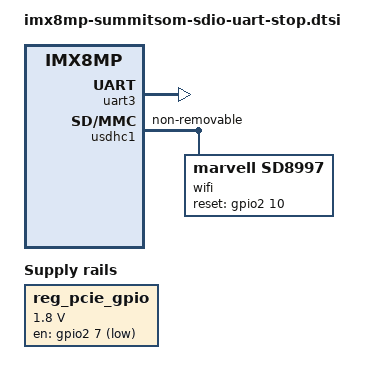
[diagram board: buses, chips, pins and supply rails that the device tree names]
// SPDX-License-Identifier: (GPL-2.0+ OR MIT)
/*
 * Copyright 2022 Laird Connectivity
 */

/ {
	reg_pcie_gpio: regulator-pcie-gpio {
		pinctrl-names = "default";
		pinctrl-0 = <&pinctrl_pcie_disable &pinctrl_pcie_reset>;

		compatible = "regulator-fixed";

		regulator-name = "PCIE GPIO";
		regulator-min-microvolt = <1800000>;
		regulator-max-microvolt = <1800000>;

		gpios = <&gpio2 7 GPIO_ACTIVE_HIGH>;
		enable-active-low;
		regulator-always-on;
	};
};

&uart3 {
	/* BT */
 	status = "okay";
};

&usdhc1 {
	pinctrl-0 = <&pinctrl_usdhc1>, <&pinctrl_wifi_pmu>, <&pinctrl_wifibs>;
	pinctrl-1 = <&pinctrl_usdhc1_100mhz>, <&pinctrl_wifi_pmu>, <&pinctrl_wifibs>;
	pinctrl-2 = <&pinctrl_usdhc1_200mhz>, <&pinctrl_wifi_pmu>, <&pinctrl_wifibs>;

	status = "okay";

	assigned-clocks = <&clk IMX8MP_CLK_USDHC1>;
	assigned-clock-rates = <400000000>;

	fsl,sdio-async-interrupt-enabled;

	non-removable;

	wifi: wifi {
		compatible = "marvell,sd8997";
		//interrupts-extended = <&gpio3 14 GPIO_ACTIVE_LOW>;
		reset-gpios = <&gpio2 10 GPIO_ACTIVE_HIGH>;
		remove-power-on-link-down;
	};
};

&wifi_wake {
	gpios = <&gpio3 14 GPIO_ACTIVE_LOW>;
};

&pinctrl_wifi_pmu {
	fsl,pins = <
		MX8MP_IOMUXC_SD1_RESET_B__GPIO2_IO10       0x00000140
	>;
};
